# MLDR187 register map
File version: 1.4
CPU: MDR32F02, little endian
Registers are 32-bit, read-write, no defined reset value unless marked. A register's access mark holds for its fields unless they carry their own. Offsets are from the block's base; [hi:lo] are bit positions; {n}, {i} and the like mark numbered series; 'fields as' and 'values as' point back to an identical list.

## WWDG — WWDG description
Base 0x40048000
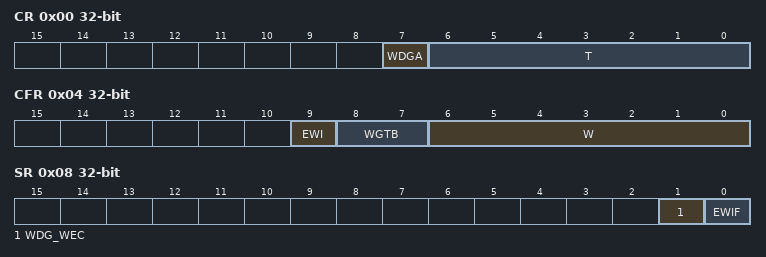
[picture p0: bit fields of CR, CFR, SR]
0x00 CR — CR description
  [7] WDGA — WDGA description
  [6:0] T — T description
0x04 CFR — CFR description
  [9] EWI — EWI description
  [8:7] WGTB — WGTB description
  [6:0] W — W description
0x08 SR — SR description
  [1] WDG_WEC — WDG_WEC description
  [0] EWIF — EWIF description

## IWDG — IWDG description
Base 0x40050000
0x00 KR — KR description
  [15:0] KEY — KEY description
0x04 PR — PR description
  [2:0] PR
0x08 RLR — RLR description
  [11:0] RLR
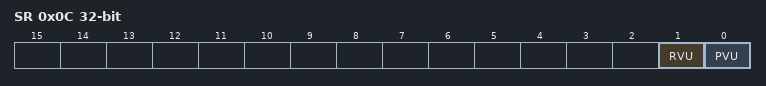
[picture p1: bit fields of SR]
0x0C SR — SR description
  [1] RVU — RVU description
  [0] PVU — PVU description

## ISO7816 — ISO7816 description
Base 0x400C0000
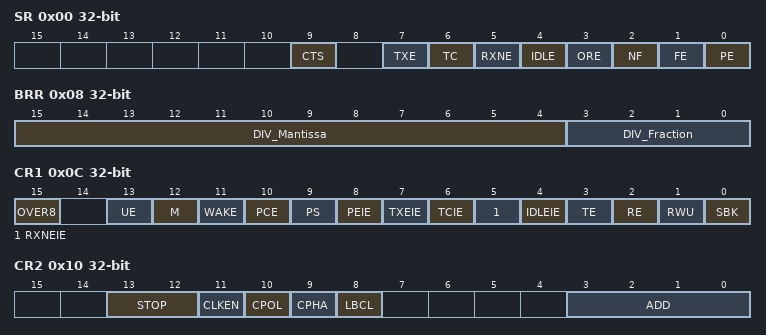
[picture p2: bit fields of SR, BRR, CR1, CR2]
0x00 SR — Status register
  [9] CTS — CTS flag
  [7] TXE — TX empty
  [6] TC — Transmit complete
  [5] RXNE — Read data register not empty
  [4] IDLE — IDLE line detected
  [3] ORE — Overrun error
  [2] NF — Noise error flag
  [1] FE — Frame error
  [0] PE — Parity error
0x04 DR — Data register
  [8:0] DR
0x08 BRR — Baud rate register
  [15:4] DIV_Mantissa, [3:0] DIV_Fraction
0x0C CR1 — Control register 1
  [15] OVER8 — Oversampling mode
  [13] UE — USART Enable
  [12] M — Byte len. 1 - 9;0 - 8
  [11] WAKE — Wake bit
  [10] PCE — Parity control enable
  [9] PS — Parity selection
  [8] PEIE — PE interrupt enable
  [7] TXEIE — TXE interrupt enable
  [6] TCIE — Transmission complete interrupt enable
  [5] RXNEIE — RXNE interrupt enable
  [4] IDLEIE — IDLE interrupt enable
  [3] TE — Transmitter enable
  [2] RE — Receiver enable
  [1] RWU — Receiver wakeup
  [0] SBK — Send break
0x10 CR2 — Control register 2
  [13:12] STOP — Stop bit type mask
  [11] CLKEN — Clock enable
  [10] CPOL — Clock polarity
  [9] CPHA — Clock phase
  [8] LBCL — Last bit clock pulse
  [3:0] ADD — Address of the USART node
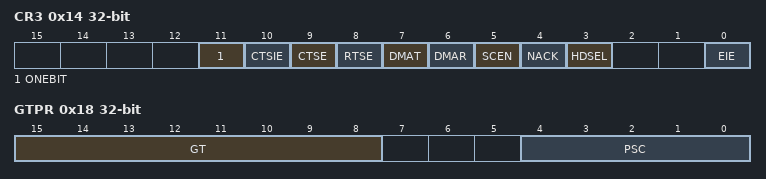
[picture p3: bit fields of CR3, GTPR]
0x14 CR3 — Control register 3
  [11] ONEBIT — One sample per bit mode resolution
  [10] CTSIE — CTS interrupt enable
  [9] CTSE — CTS enable
  [8] RTSE — RTS enable
  [7] DMAT — DMA enable transmitter
  [6] DMAR — DMA enable receiver
  [5] SCEN — Smartcard mode enable
  [4] NACK — Smartcard NACK
  [3] HDSEL — Half-duplex selection
  [0] EIE — Error interrupt enable
0x18 GTPR — Guard time and prescaler register
  [15:8] GT — GT description
  [4:0] PSC — PSC description

## BKP — BKP description
Base 0x40060000
0x00 BKP_WPR — WPR description
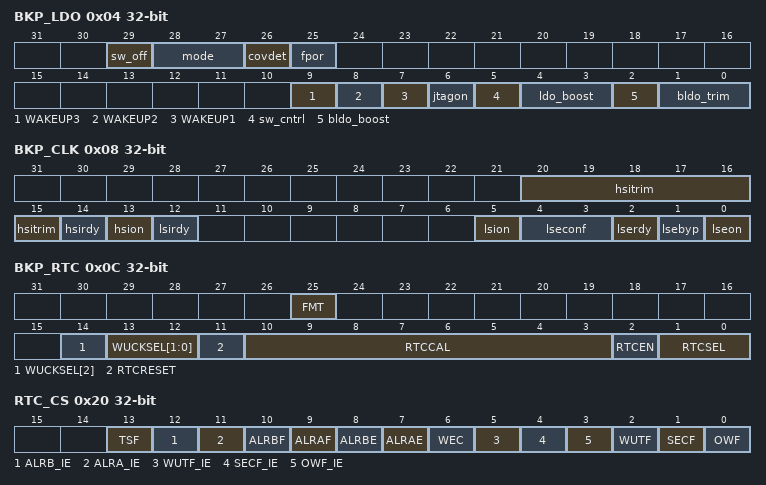
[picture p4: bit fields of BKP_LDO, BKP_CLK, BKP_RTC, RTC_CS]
0x04 BKP_LDO — LDO description
  [29] sw_off — sw_off description
  [28:27] mode — mode description
  [26] covdet — covdet description
  [25] fpor — fpor description
  [9] WAKEUP3 ro — WAKEUP3 description
  [8] WAKEUP2 ro — WAKEUP2 description
  [7] WAKEUP1 ro — WAKEUP1 description
  [6] jtagon — jtagon description
  [5] sw_cntrl — sw_cntrl description
  [4:3] ldo_boost — ldo_boost description
  [2] bldo_boost — bldo_boost description
  [1:0] bldo_trim — bldo_trim description
0x08 BKP_CLK — CLK description
  [20:15] hsitrim — hsitrim description
  [14] hsirdy ro — hsirdy description
  [13] hsion — hsion description
  [12] lsirdy ro — lsirdy description
  [5] lsion — lsion description
  [4:3] lseconf — lseconf description
  [2] lserdy ro — lserdy description
  [1] lsebyp — lsebyp description
  [0] lseon — lseon description
0x0C BKP_RTC — RTC description
  [25] FMT — FMT description
  [14] WUCKSEL[2] — WUCKSEL[2] description
  [13:12] WUCKSEL[1:0] — WUCKSEL[1:0] description
  [11] RTCRESET — RTCRESET description
  [10:3] RTCCAL — RTCCAL description
  [2] RTCEN — RTCEN description
  [1:0] RTCSEL — RTCSEL description
0x10 RTC_WUTR — RTC_WUTR description
0x14 RTC_PREDIV_S — RTC_PREDIV_S description
  [19:0] RTCDIV — RTCDIV description
0x18 RTC_PRL — RTC_PRL description
  [19:0] RTCPRL — RTCPRL description
0x1C RTC_ALRM — RTC_ALRM description
0x20 RTC_CS — RTC_CS description
  [13] TSF — TSF description
  [12] ALRB_IE — ALRB_IE description
  [11] ALRA_IE — ALRA_IE description
  [10] ALRBF — ALRBF description
  [9] ALRAF — ALRAF description
  [8] ALRBE — ALRBE description
  [7] ALRAE — ALRAE description
  [6] WEC ro — WEC description
  [5] WUTF_IE — WUTF_IE description
  [4] SECF_IE — SECF_IE description
  [3] OWF_IE — OWF_IE description
  [2] WUTF — WUTF description
  [1] SECF — SECF description
  [0] OWF — OWF description
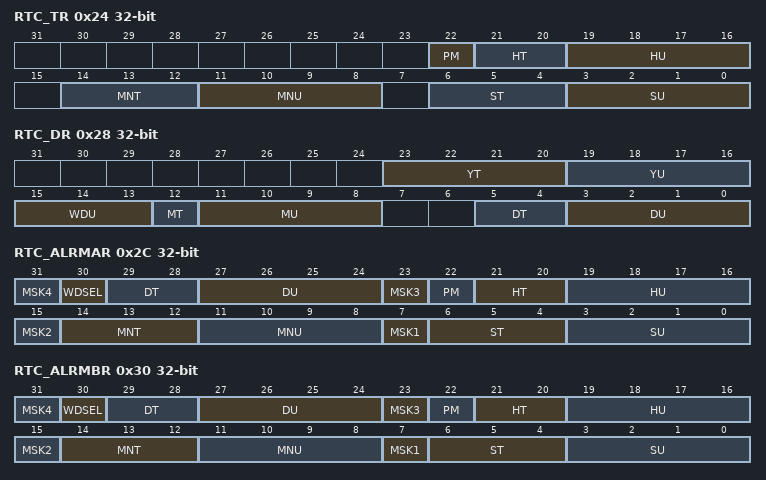
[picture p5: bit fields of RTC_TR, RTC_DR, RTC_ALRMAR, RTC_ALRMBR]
0x24 RTC_TR — RTC_TR description
  [22] PM — PM description
  [21:20] HT — HT description
  [19:16] HU — HU description
  [14:12] MNT — MNT description
  [11:8] MNU — MNU description
  [6:4] ST — ST description
  [3:0] SU — SU description
0x28 RTC_DR — RTC_DR description
  [23:20] YT — YT description
  [19:16] YU — YU description
  [15:13] WDU — WDU description
  [12] MT — MT description
  [11:8] MU — MU description
  [5:4] DT — DT description
  [3:0] DU — DU description
0x2C RTC_ALRMAR — RTC_ALRMAR description
  [8n-1] MSK{n} (n=1..4) — MSK{n} description
  [30] WDSEL — WDSEL description
  [29:28] DT — DT description
  [27:24] DU — DU description
  [22] PM — PM description
  [21:20] HT — HT description
  [19:16] HU — HU description
  [14:12] MNT — MNT description
  [11:8] MNU — MNU description
  [6:4] ST — ST description
  [3:0] SU — SU description
0x30 RTC_ALRMBR — RTC_ALRMBR description
  fields as RTC_ALRMAR
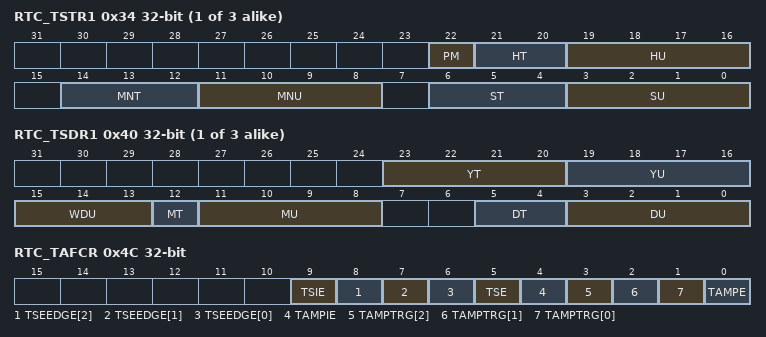
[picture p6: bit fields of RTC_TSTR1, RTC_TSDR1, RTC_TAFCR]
{0x30+4i} RTC_TSTR{i} (i=1..3) — RTC_TSTR{i} description
  fields as RTC_TR
{0x3C+4i} RTC_TSDR{i} (i=1..3) — RTC_TSDR{i} description
  fields as RTC_DR
0x4C RTC_TAFCR — RTC_TAFCR description
  [9] TSIE — TSIE description
  [8] TSEEDGE[2] — TSEEDGE[2] description
  [7] TSEEDGE[1] — TSEEDGE[1] description
  [6] TSEEDGE[0] — TSEEDGE[0] description
  [5] TSE — TSE description
  [4] TAMPIE — TAMPIE description
  [3] TAMPTRG[2] — TAMPTRG[2] description
  [2] TAMPTRG[1] — TAMPTRG[1] description
  [1] TAMPTRG[0] — TAMPTRG[0] description
  [0] TAMPE — TAMPE description
